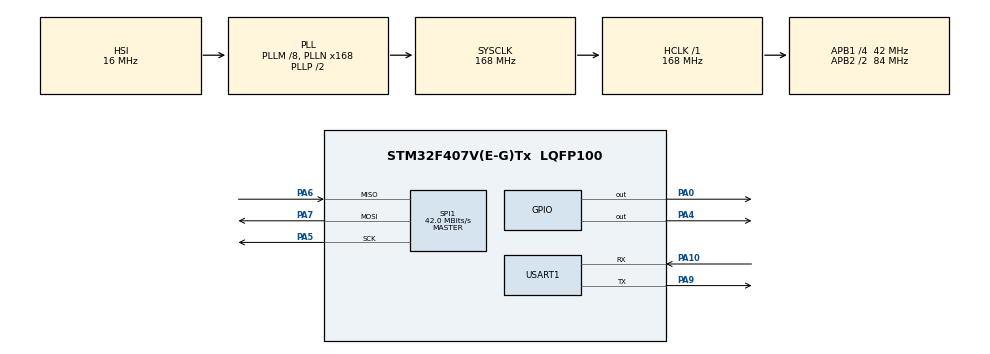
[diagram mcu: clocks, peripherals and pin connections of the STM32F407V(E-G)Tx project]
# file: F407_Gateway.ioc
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FREERTOS.Tasks01=defaultTask,0,128,StartDefaultTask,Default,NULL,Dynamic,NULL,NULL
FREERTOS.configTOTAL_HEAP_SIZE=20480
Mcu.Family=STM32F4
Mcu.Name=STM32F407V(E-G)Tx
Mcu.Package=LQFP100
NVIC.PriorityGroup=NVIC_PRIORITYGROUP_4
PA0-WKUP.Signal=GPIO_Output
PA10.Mode=Asynchronous
PA10.Signal=USART1_RX
PA13.Mode=Serial_Wire
PA13.Signal=SYS_JTMS-SWDIO
PA14.Mode=Serial_Wire
PA14.Signal=SYS_JTCK-SWCLK
PA4.GPIO_Speed=GPIO_SPEED_FREQ_VERY_HIGH
PA4.PinState=GPIO_PIN_SET
PA4.Signal=GPIO_Output
PA5.Mode=Full_Duplex_Master
PA5.Signal=SPI1_SCK
PA6.Mode=Full_Duplex_Master
PA6.Signal=SPI1_MISO
PA7.Mode=Full_Duplex_Master
PA7.Signal=SPI1_MOSI
PA9.Mode=Asynchronous
PA9.Signal=USART1_TX
PH0-OSC_IN.Mode=HSE-External-Oscillator
PH0-OSC_IN.Signal=RCC_OSC_IN
PH1-OSC_OUT.Mode=HSE-External-Oscillator
PH1-OSC_OUT.Signal=RCC_OSC_OUT
ProjectManager.HeapSize=0x200
ProjectManager.StackSize=0x400
ProjectManager.TargetToolchain=STM32CubeIDE
RCC.48MHZClocksFreq_Value=84000000
RCC.AHBFreq_Value=168000000
RCC.APB1CLKDivider=RCC_HCLK_DIV4
RCC.APB1Freq_Value=42000000
RCC.APB1TimFreq_Value=84000000
RCC.APB2CLKDivider=RCC_HCLK_DIV2
RCC.APB2Freq_Value=84000000
RCC.APB2TimFreq_Value=168000000
RCC.CortexFreq_Value=168000000
RCC.HCLKFreq_Value=168000000
RCC.HSE_VALUE=25000000
RCC.HSI_VALUE=16000000
RCC.LSE_VALUE=32768
RCC.PLLM=8
RCC.PLLN=168
RCC.SYSCLKFreq_VALUE=168000000
RCC.SYSCLKSource=RCC_SYSCLKSOURCE_PLLCLK
RCC.VCOOutputFreq_Value=336000000
SPI1.CalculateBaudRate=42.0 MBits/s
SPI1.Direction=SPI_DIRECTION_2LINES
SPI1.Mode=SPI_MODE_MASTER
SPI1.VirtualType=VM_MASTER
USART1.VirtualMode=VM_ASYNC
VP_FREERTOS_VS_CMSIS_V1.Mode=CMSIS_V1
board=custom

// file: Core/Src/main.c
/* USER CODE BEGIN Header */
/**
  ******************************************************************************
  * @file           : main.c
  * @brief          : Main program body
  ******************************************************************************
  * @attention
  *
  * Copyright (c) 2026 STMicroelectronics.
  * All rights reserved.
  *
  * This software is licensed under terms that can be found in the LICENSE file
  * in the root directory of this software component.
  * If no LICENSE file comes with this software, it is provided AS-IS.
  *
  ******************************************************************************
  */
/* USER CODE END Header */
#include "main.h"
#include "cmsis_os.h"

/* USER CODE BEGIN Includes */
#include "stdio.h"       //提供 `printf` 的声明
#include "string.h"
/* USER CODE END Includes */

SPI_HandleTypeDef hspi1;

UART_HandleTypeDef huart1;

osThreadId defaultTaskHandle;
/* USER CODE BEGIN PV */
osMessageQId myQueueHandle;   //定于队列句柄
osSemaphoreId mySemHandle;    //定义信号量句柄
osMutexId myMutexHandle;      //定义互斥量句柄
/* USER CODE END PV */

void SystemClock_Config(void);
static void MX_GPIO_Init(void);
static void MX_SPI1_Init(void);
static void MX_USART1_UART_Init(void);
void StartDefaultTask(void const * argument);

/* USER CODE BEGIN PFP */
void StartProducerTask(void const * argument); //生产者任务
void StartConsumerTask(void const * argument); //消费者任务
void StartSemaphoreTask(void const * argument);//信号量任务
uint32_t W25Q128_ReadID(void);                 //W25Q128
void W25Q128_WriteEnable(void);
void W25Q128_WaitBusy(void);
void W25Q128_SectorErase(uint32_t addr);
void W25Q128_PageWrite(uint32_t addr, uint8_t *data, uint16_t len);
void W25Q128_ReadData(uint32_t addr, uint8_t *buf, uint16_t len);
/* USER CODE END PFP */

/* USER CODE BEGIN 0 */
int __io_putchar(int ch)
{
    HAL_UART_Transmit(&huart1, (uint8_t *)&ch, 1, 0xFFFF);
    return ch;
}
/* USER CODE END 0 */

int main(void)
{

  /* MCU Configuration--------------------------------------------------------*/

  /* Reset of all peripherals, Initializes the Flash interface and the Systick. */
  HAL_Init();

  /* Configure the system clock */
  SystemClock_Config();

  /* Initialize all configured peripherals */
  MX_GPIO_Init();
  MX_SPI1_Init();
  MX_USART1_UART_Init();

  /* USER CODE BEGIN RTOS_MUTEX */
  osMutexDef(myMutex);//定义互斥量
  myMutexHandle = osMutexCreate(osMutex(myMutex));//创建互斥量
  /* add mutexes, ... */
  /* USER CODE END RTOS_MUTEX */

  /* USER CODE BEGIN RTOS_SEMAPHORES */
  osSemaphoreDef(mySem);//定信号量
  mySemHandle = osSemaphoreCreate(osSemaphore(mySem), 1);//创建信号量
  /* add semaphores, ... */
  /* USER CODE END RTOS_SEMAPHORES */

  /* USER CODE BEGIN RTOS_QUEUES */
  osMessageQDef(myQueue, 10, uint32_t);//定义队列
  myQueueHandle = osMessageCreate(osMessageQ(myQueue), NULL);//创建队列
  /* add queues, ... */
  /* USER CODE END RTOS_QUEUES */

  /* Create the thread(s) */
  /* definition and creation of defaultTask */
  osThreadDef(defaultTask, StartDefaultTask, osPriorityNormal, 0, 256);
  defaultTaskHandle = osThreadCreate(osThread(defaultTask), NULL);

  /* USER CODE BEGIN RTOS_THREADS */
  osThreadDef(producerTask, StartProducerTask, osPriorityNormal, 0, 128);//定义生产者任务
  osThreadCreate(osThread(producerTask), NULL);//创建生产者任务

  osThreadDef(consumerTask, StartConsumerTask, osPriorityNormal, 0, 128);//定义消费者任务
  osThreadCreate(osThread(consumerTask), NULL);//创建消费者任务

  osThreadDef(semaphoreTask, StartSemaphoreTask, osPriorityNormal, 0, 128);//定义信号量任务
  osThreadCreate(osThread(semaphoreTask), NULL);//创建信号量任务
  /* add threads, ... */
  /* USER CODE END RTOS_THREADS */

  /* Start scheduler */
  osKernelStart();

  /* We should never get here as control is now taken by the scheduler */

  /* Infinite loop */
  while (1)
  {

  }
}

void SystemClock_Config(void)
{
  RCC_OscInitTypeDef RCC_OscInitStruct = {0};
  RCC_ClkInitTypeDef RCC_ClkInitStruct = {0};

  /** Configure the main internal regulator output voltage
  */
  __HAL_RCC_PWR_CLK_ENABLE();
  __HAL_PWR_VOLTAGESCALING_CONFIG(PWR_REGULATOR_VOLTAGE_SCALE1);

  /** Initializes the RCC Oscillators according to the specified parameters
  * in the RCC_OscInitTypeDef structure.
  */
  RCC_OscInitStruct.OscillatorType = RCC_OSCILLATORTYPE_HSI;
  RCC_OscInitStruct.HSIState = RCC_HSI_ON;
  RCC_OscInitStruct.HSICalibrationValue = RCC_HSICALIBRATION_DEFAULT;
  RCC_OscInitStruct.PLL.PLLState = RCC_PLL_ON;
  RCC_OscInitStruct.PLL.PLLSource = RCC_PLLSOURCE_HSI;
  RCC_OscInitStruct.PLL.PLLM = 8;
  RCC_OscInitStruct.PLL.PLLN = 168;
  RCC_OscInitStruct.PLL.PLLP = RCC_PLLP_DIV2;
  RCC_OscInitStruct.PLL.PLLQ = 4;
  if (HAL_RCC_OscConfig(&RCC_OscInitStruct) != HAL_OK)
  {
    Error_Handler();
  }

  /** Initializes the CPU, AHB and APB buses clocks
  */
  RCC_ClkInitStruct.ClockType = RCC_CLOCKTYPE_HCLK|RCC_CLOCKTYPE_SYSCLK
                              |RCC_CLOCKTYPE_PCLK1|RCC_CLOCKTYPE_PCLK2;
  RCC_ClkInitStruct.SYSCLKSource = RCC_SYSCLKSOURCE_PLLCLK;
  RCC_ClkInitStruct.AHBCLKDivider = RCC_SYSCLK_DIV1;
  RCC_ClkInitStruct.APB1CLKDivider = RCC_HCLK_DIV4;
  RCC_ClkInitStruct.APB2CLKDivider = RCC_HCLK_DIV2;

  if (HAL_RCC_ClockConfig(&RCC_ClkInitStruct, FLASH_LATENCY_5) != HAL_OK)
  {
    Error_Handler();
  }
}

static void MX_SPI1_Init(void)
{

  /* SPI1 parameter configuration*/
  hspi1.Instance = SPI1;
  hspi1.Init.Mode = SPI_MODE_MASTER;
  hspi1.Init.Direction = SPI_DIRECTION_2LINES;
  hspi1.Init.DataSize = SPI_DATASIZE_8BIT;
  hspi1.Init.CLKPolarity = SPI_POLARITY_LOW;
  hspi1.Init.CLKPhase = SPI_PHASE_1EDGE;
  hspi1.Init.NSS = SPI_NSS_SOFT;
  hspi1.Init.BaudRatePrescaler = SPI_BAUDRATEPRESCALER_2;
  hspi1.Init.FirstBit = SPI_FIRSTBIT_MSB;
  hspi1.Init.TIMode = SPI_TIMODE_DISABLE;
  hspi1.Init.CRCCalculation = SPI_CRCCALCULATION_DISABLE;
  hspi1.Init.CRCPolynomial = 10;
  if (HAL_SPI_Init(&hspi1) != HAL_OK)
  {
    Error_Handler();
  }

}

static void MX_USART1_UART_Init(void)
{

  huart1.Instance = USART1;
  huart1.Init.BaudRate = 115200;
  huart1.Init.WordLength = UART_WORDLENGTH_8B;
  huart1.Init.StopBits = UART_STOPBITS_1;
  huart1.Init.Parity = UART_PARITY_NONE;
  huart1.Init.Mode = UART_MODE_TX_RX;
  huart1.Init.HwFlowCtl = UART_HWCONTROL_NONE;
  huart1.Init.OverSampling = UART_OVERSAMPLING_16;
  if (HAL_UART_Init(&huart1) != HAL_OK)
  {
    Error_Handler();
  }

}

static void MX_GPIO_Init(void)
{
  GPIO_InitTypeDef GPIO_InitStruct = {0};

  /* GPIO Ports Clock Enable */
  __HAL_RCC_GPIOH_CLK_ENABLE();
  __HAL_RCC_GPIOA_CLK_ENABLE();
  __HAL_RCC_GPIOB_CLK_ENABLE();

  /*Configure GPIO pin Output Level */
  HAL_GPIO_WritePin(GPIOA, GPIO_PIN_4, GPIO_PIN_SET);

  /*Configure GPIO pin Output Level */
  HAL_GPIO_WritePin(GPIOB, GPIO_PIN_2, GPIO_PIN_RESET);

  /*Configure GPIO pin : PA0 */
  GPIO_InitStruct.Pin = GPIO_PIN_0;
  GPIO_InitStruct.Mode = GPIO_MODE_INPUT;
  GPIO_InitStruct.Pull = GPIO_PULLUP;
  HAL_GPIO_Init(GPIOA, &GPIO_InitStruct);

  /*Configure GPIO pin : PA4 */
  GPIO_InitStruct.Pin = GPIO_PIN_4;
  GPIO_InitStruct.Mode = GPIO_MODE_OUTPUT_PP;
  GPIO_InitStruct.Pull = GPIO_NOPULL;
  GPIO_InitStruct.Speed = GPIO_SPEED_FREQ_VERY_HIGH;
  HAL_GPIO_Init(GPIOA, &GPIO_InitStruct);

  /*Configure GPIO pin : PB2 */
  GPIO_InitStruct.Pin = GPIO_PIN_2;
  GPIO_InitStruct.Mode = GPIO_MODE_OUTPUT_PP;
  GPIO_InitStruct.Pull = GPIO_NOPULL;
  GPIO_InitStruct.Speed = GPIO_SPEED_FREQ_LOW;
  HAL_GPIO_Init(GPIOB, &GPIO_InitStruct);

}

/* USER CODE BEGIN 4 */
void StartSemaphoreTask(void const * argument)
{
    for(;;)
    {
        if(osSemaphoreWait(mySemHandle, osWaitForever) == osOK)//等待信号量
        {
        	osMutexWait(myMutexHandle, osWaitForever);
            printf("Semaphore received!\r\n");
            osMutexRelease(myMutexHandle);
        }
    }
}

void StartProducerTask(void const * argument)
{
    uint32_t count = 0;//计数器
    for(;;)
    {
    	count++;
    	osMessagePut(myQueueHandle, count, osWaitForever);//把数据放进队列
    	osMutexWait(myMutexHandle, osWaitForever);//拿锁
    	printf("Producer: %lu\r\n", count);//打印
    	osMutexRelease(myMutexHandle);//放锁
    	osDelay(1000);
    }
}

void StartConsumerTask(void const * argument)
{
    osEvent event;//接收队列数据
    for(;;)
    {
        event = osMessageGet(myQueueHandle, osWaitForever);//从队列取数据
        if(event.status == osEventMessage)//判断数据是否是信息
        {
        	osMutexWait(myMutexHandle, osWaitForever);//拿锁
        	printf("Consumer: %lu\r\n", event.value.v);
        	osMutexRelease(myMutexHandle);//放锁
        }
    }
}

uint32_t W25Q128_ReadID(void)
{
    uint8_t cmd = 0x9F;        // 读 ID 命令
    uint8_t id[3] = {0};       // 存 3 个字节的 ID
    uint32_t flash_id = 0;

    // 1. 拉低 CS，选中 W25Q128
    HAL_GPIO_WritePin(GPIOA, GPIO_PIN_4, GPIO_PIN_RESET);

    // 2. 发送读 ID 命令
    HAL_SPI_Transmit(&hspi1, &cmd, 1, 100);

    // 3. 读取 3 个字节的 ID
    HAL_SPI_Receive(&hspi1, id, 3, 100);

    // 4. 拉高 CS，取消选中
    HAL_GPIO_WritePin(GPIOA, GPIO_PIN_4, GPIO_PIN_SET);

    // 5. 拼接成 32 位 ID
    flash_id = (id[0] << 16) | (id[1] << 8) | id[2];

    return flash_id;
}

void W25Q128_WriteEnable(void)
{
    uint8_t cmd = 0x06;
    HAL_GPIO_WritePin(GPIOA, GPIO_PIN_4, GPIO_PIN_RESET);
    HAL_SPI_Transmit(&hspi1, &cmd, 1, 100);
    HAL_GPIO_WritePin(GPIOA, GPIO_PIN_4, GPIO_PIN_SET);
}

void W25Q128_WaitBusy(void)
{
    uint8_t cmd = 0x05;
    uint8_t status = 0;
    HAL_GPIO_WritePin(GPIOA, GPIO_PIN_4, GPIO_PIN_RESET);
    HAL_SPI_Transmit(&hspi1, &cmd, 1, 100);
    do {
        HAL_SPI_Receive(&hspi1, &status, 1, 100);
    } while(status & 0x01);
    HAL_GPIO_WritePin(GPIOA, GPIO_PIN_4, GPIO_PIN_SET);
}

void W25Q128_SectorErase(uint32_t addr)
{
    uint8_t cmd = 0x20;
    uint8_t addr_buf[3];
    addr_buf[0] = (addr >> 16) & 0xFF;
    addr_buf[1] = (addr >> 8) & 0xFF;
    addr_buf[2] = addr & 0xFF;

    W25Q128_WriteEnable();
    HAL_GPIO_WritePin(GPIOA, GPIO_PIN_4, GPIO_PIN_RESET);
    HAL_SPI_Transmit(&hspi1, &cmd, 1, 100);
    HAL_SPI_Transmit(&hspi1, addr_buf, 3, 100);
    HAL_GPIO_WritePin(GPIOA, GPIO_PIN_4, GPIO_PIN_SET);
    W25Q128_WaitBusy();
}

void W25Q128_PageWrite(uint32_t addr, uint8_t *data, uint16_t len)
{
    uint8_t cmd = 0x02;
    uint8_t addr_buf[3];
    addr_buf[0] = (addr >> 16) & 0xFF;
    addr_buf[1] = (addr >> 8) & 0xFF;
    addr_buf[2] = addr & 0xFF;

    W25Q128_WriteEnable();
    HAL_GPIO_WritePin(GPIOA, GPIO_PIN_4, GPIO_PIN_RESET);
    HAL_SPI_Transmit(&hspi1, &cmd, 1, 100);
    HAL_SPI_Transmit(&hspi1, addr_buf, 3, 100);
    HAL_SPI_Transmit(&hspi1, data, len, 100);
    HAL_GPIO_WritePin(GPIOA, GPIO_PIN_4, GPIO_PIN_SET);
    W25Q128_WaitBusy();
}

void W25Q128_ReadData(uint32_t addr, uint8_t *buf, uint16_t len)
{
    uint8_t cmd = 0x03;
    uint8_t addr_buf[3];
    addr_buf[0] = (addr >> 16) & 0xFF;
    addr_buf[1] = (addr >> 8) & 0xFF;
    addr_buf[2] = addr & 0xFF;

    HAL_GPIO_WritePin(GPIOA, GPIO_PIN_4, GPIO_PIN_RESET);
    HAL_SPI_Transmit(&hspi1, &cmd, 1, 100);
    HAL_SPI_Transmit(&hspi1, addr_buf, 3, 100);
    HAL_SPI_Receive(&hspi1, buf, len, 100);
    HAL_GPIO_WritePin(GPIOA, GPIO_PIN_4, GPIO_PIN_SET);
}
/* USER CODE END 4 */

void StartDefaultTask(void const * argument)
{
  /* USER CODE BEGIN 5 */
 /* Infinite loop */
	uint8_t write_buf[16] = "Hello W25Q128!";
	uint8_t read_buf[16] = {0};

	for(;;)
	{
		osMutexWait(myMutexHandle, osWaitForever);

		W25Q128_SectorErase(0x000000);
		W25Q128_PageWrite(0x000000, write_buf, 14);
		W25Q128_ReadData(0x000000, read_buf, 14);

		if(memcmp(write_buf, read_buf, 14) == 0)
		{
			printf("Write/Read OK: %s\r\n", read_buf);
		}
			else
		{
			printf("Write/Read FAIL\r\n");
		}

	    HAL_GPIO_TogglePin(GPIOB, GPIO_PIN_2); //点灯
	    printf("LED Toggle\r\n");

	    uint32_t id = W25Q128_ReadID();        //读w25ID
	    printf("W25Q128 ID: 0x%06lX\r\n", id);

	    printf("DefaultTask stack: %lu\r\n", uxTaskGetStackHighWaterMark(NULL));//查看栈历史最小剩余容量

	    osMutexRelease(myMutexHandle);

	    osDelay(1000);
	}
  /* USER CODE END 5 */
}

void Error_Handler(void)
{
  __disable_irq();
  while (1)
  {
  }
}
